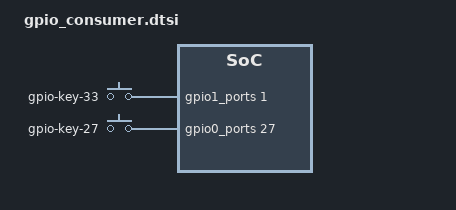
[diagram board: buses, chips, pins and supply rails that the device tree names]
/* Copyright (c) 2023, Canaan Bright Sight Co., Ltd
 *
 * This program is free software; you can redistribute it and/or modify
 * it under the terms of the GNU General Public License version 2 as
 * published by the Free Software Foundation.
*/
#include <dt-bindings/gpio/gpio.h>
/ {
        gpio_key: gpio_keys {
            compatible = "gpio-keys";
            key1 {
                label = "gpio-key-33";
                linux,code = <103>;
                gpios = <&gpio1_ports 1 GPIO_ACTIVE_HIGH>;
                debounce-interval = <3>;
            };

            key2 {
                label = "gpio-key-27";
                linux,code = <108>;
                gpios = <&gpio0_ports 27 GPIO_ACTIVE_HIGH>;
                debounce-interval = <3>;
            };
        };
};

&gpio0 {
    status = "okay";
};

&gpio1 {
    status = "okay";
};
